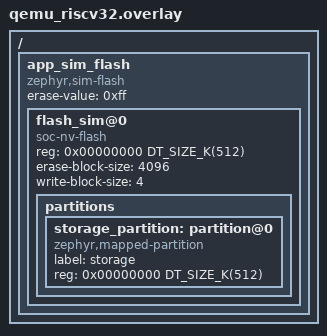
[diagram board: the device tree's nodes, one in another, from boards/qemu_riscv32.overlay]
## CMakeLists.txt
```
# SPDX-License-Identifier: Apache-2.0

cmake_minimum_required(VERSION 3.20.0)
find_package(Zephyr REQUIRED HINTS $ENV{ZEPHYR_BASE})
project(app_fs_sandbox)

zephyr_syscall_header(${CMAKE_CURRENT_SOURCE_DIR}/src/fs_svc.h)

target_sources(app PRIVATE
  src/main.c
  src/fs_broker.c
  src/fs_svc.c
)
```

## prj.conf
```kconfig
CONFIG_USERSPACE=y
CONFIG_APPLICATION_DEFINED_SYSCALL=y

CONFIG_FLASH=y
CONFIG_FLASH_MAP=y
CONFIG_FILE_SYSTEM=y
CONFIG_FILE_SYSTEM_LITTLEFS=y

CONFIG_LOG=y
CONFIG_LOG_MODE_MINIMAL=y
CONFIG_THREAD_NAME=y

CONFIG_MAIN_STACK_SIZE=4096
CONFIG_HEAP_MEM_POOL_SIZE=16384
CONFIG_PRIVILEGED_STACK_SIZE=3072
```

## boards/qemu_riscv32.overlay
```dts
/*
 * Copyright (c) 2026 Espressif Systems (Shanghai) Co., Ltd.
 *
 * SPDX-License-Identifier: Apache-2.0
 */

#include <mem.h>

/* QEMU has no flash for the application store: back the storage partition
 * with the flash simulator.
 */
/ {
	app_sim_flash: app_sim_flash {
		compatible = "zephyr,sim-flash";
		#address-cells = <1>;
		#size-cells = <1>;
		erase-value = <0xff>;

		flash_sim@0 {
			compatible = "soc-nv-flash";
			reg = <0x00000000 DT_SIZE_K(512)>;
			erase-block-size = <4096>;
			write-block-size = <4>;

			partitions {
				ranges;
				#address-cells = <1>;
				#size-cells = <1>;

				storage_partition: partition@0 {
					compatible = "zephyr,mapped-partition";
					label = "storage";
					reg = <0x00000000 DT_SIZE_K(512)>;
				};
			};
		};
	};
};
```

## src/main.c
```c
/*
 * Copyright (c) 2026 Espressif Systems (Shanghai) Co., Ltd.
 *
 * SPDX-License-Identifier: Apache-2.0
 */

/*
 * Per-app sandboxed filesystem. The app reads and writes files in its own
 * private namespace as if it had a whole filesystem, but it is confined to that
 * subtree: a path that tries to escape (absolute, or containing "..") is denied
 * by the broker before any real filesystem access. This is the namespaced
 * storage capability - one shared filesystem, private per-app views.
 */

#include "fs_svc.h"
#include "fs_broker.h"

#include <zephyr/kernel.h>
#include <zephyr/sys/printk.h>
#include <string.h>

#define STACK_SIZE 2048
#define APP_PRIO   5

K_THREAD_STACK_DEFINE(app_stack, STACK_SIZE);
static struct k_thread app_thread;

static void app_entry(void *p1, void *p2, void *p3)
{
	ARG_UNUSED(p1); ARG_UNUSED(p2); ARG_UNUSED(p3);

	printk("\n=== app uses its own private storage ===\n");

	/* Write a file in the app's own namespace. */
	int h = app_file_open("config.txt", 1);

	if (h >= 0) {
		const char *data = "brightness=80\n";

		app_file_write(h, data, strlen(data));
		app_file_close(h);
		printk("  [app] wrote config.txt\n");
	}

	/* Read it back. */
	h = app_file_open("config.txt", 0);
	if (h >= 0) {
		char buf[32] = {0};
		int n = app_file_read(h, buf, sizeof(buf) - 1);

		app_file_close(h);
		printk("  [app] read config.txt (%d bytes): %s", n, buf);
	}

	/* Now try to ESCAPE the sandbox - these must all be denied. */
	printk("\n=== app tries to escape its sandbox (must be denied) ===\n");

	printk("  [app] try '../1/secret.txt' (another app's dir)...\n");
	int rc = app_file_open("../1/secret.txt", 0);

	printk("  [app] -> rc=%d (%s)\n", rc, rc < 0 ? "DENIED" : "LEAKED!");

	printk("  [app] try '/lfs/system/keys' (absolute, system path)...\n");
	rc = app_file_open("/lfs/system/keys", 0);
	printk("  [app] -> rc=%d (%s)\n", rc, rc < 0 ? "DENIED" : "LEAKED!");

	printk("  [app] try 'a/../../etc' (sneaky traversal)...\n");
	rc = app_file_open("a/../../etc", 0);
	printk("  [app] -> rc=%d (%s)\n", rc, rc < 0 ? "DENIED" : "LEAKED!");
}

int main(void)
{
	printk("\n*** per-app sandboxed filesystem (C6) ***\n");

	if (fs_broker_init() != 0) {
		printk("fs_broker_init failed\n");
		return 0;
	}

	k_tid_t t = k_thread_create(&app_thread, app_stack, STACK_SIZE, app_entry,
				    NULL, NULL, NULL, APP_PRIO, K_USER, K_FOREVER);

	/* This app gets namespace 0: /lfs/apps/0/. */
	fs_broker_register(t);

	k_thread_start(t);
	k_thread_join(t, K_FOREVER);

	printk("\n*** done: app used its private storage; all escapes denied ***\n");
	return 0;
}
```

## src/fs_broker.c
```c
/*
 * Copyright (c) 2026 Espressif Systems (Shanghai) Co., Ltd.
 *
 * SPDX-License-Identifier: Apache-2.0
 */

#include "fs_broker.h"

#include <zephyr/kernel.h>
#include <zephyr/sys/printk.h>
#include <zephyr/fs/fs.h>
#include <zephyr/fs/littlefs.h>
#include <zephyr/storage/flash_map.h>
#include <string.h>
#include <errno.h>

#define MOUNT_POINT "/lfs"

FS_LITTLEFS_DECLARE_DEFAULT_CONFIG(lfs_cfg);
static struct fs_mount_t mnt = {
	.type = FS_LITTLEFS,
	.fs_data = &lfs_cfg,
	.storage_dev = (void *)PARTITION_ID(storage_partition),
	.mnt_point = MOUNT_POINT,
};

/* Per-app namespace registry. */
static k_tid_t app_tids[FS_MAX_APPS];
static int app_n;

/* Open-file table (handles are indices). */
static struct fs_file_t files[FS_OPEN_FILES];
static bool file_used[FS_OPEN_FILES];

static int app_id_of_current(void)
{
	k_tid_t cur = k_current_get();

	for (int i = 0; i < FS_MAX_APPS; i++) {
		if (app_tids[i] == cur) {
			return i;
		}
	}
	return -1;
}

/*
 * The security-critical function: build the absolute path for the calling app
 * inside its own namespace, rejecting any attempt to escape it. A safe relative
 * path maps to "/lfs/apps/<id>/<rel>". An absolute path, or one containing a
 * ".." component, is denied.
 */
static int confine_path(int app_id, const char *rel, char *out, size_t out_sz)
{
	if (rel == NULL || rel[0] == '\0') {
		return -EINVAL;
	}
	if (rel[0] == '/') {
		printk("    [fs-broker] DENIED absolute path '%s' (escape)\n", rel);
		return -EACCES;
	}

	/* Reject any ".." path component. */
	for (const char *p = rel; *p != '\0'; p++) {
		if (p[0] == '.' && p[1] == '.' &&
		    (p[2] == '/' || p[2] == '\0') &&
		    (p == rel || p[-1] == '/')) {
			printk("    [fs-broker] DENIED path traversal '%s' (escape)\n",
			       rel);
			return -EACCES;
		}
	}

	int n = snprintk(out, out_sz, MOUNT_POINT "/apps/%d/%s", app_id, rel);

	if (n < 0 || (size_t)n >= out_sz) {
		return -ENAMETOOLONG;
	}
	return 0;
}

static int ensure_app_dir(int app_id)
{
	char dir[FS_PATH_MAX];

	(void)snprintk(dir, sizeof(dir), MOUNT_POINT "/apps");
	(void)fs_mkdir(dir);
	(void)snprintk(dir, sizeof(dir), MOUNT_POINT "/apps/%d", app_id);
	int rc = fs_mkdir(dir);

	return (rc == 0 || rc == -EEXIST) ? 0 : rc;
}

int fs_broker_init(void)
{
	int rc = fs_mount(&mnt);

	if (rc != 0 && rc != -EBUSY) {
		printk("fs-broker: mount failed: %d\n", rc);
		return rc;
	}
	(void)fs_mkdir(MOUNT_POINT "/apps");
	printk("fs-broker: filesystem mounted at %s\n", MOUNT_POINT);
	return 0;
}

int fs_broker_register(k_tid_t tid)
{
	if (app_n >= FS_MAX_APPS) {
		return -ENOSPC;
	}
	int id = app_n++;

	app_tids[id] = tid;
	ensure_app_dir(id);
	return id;
}

int fs_broker_open(const char *rel_path, bool create)
{
	int app_id = app_id_of_current();

	if (app_id < 0) {
		return -EPERM;
	}

	char path[FS_PATH_MAX];
	int rc = confine_path(app_id, rel_path, path, sizeof(path));

	if (rc != 0) {
		return rc;   /* escape denied here */
	}

	int h = -1;

	for (int i = 0; i < FS_OPEN_FILES; i++) {
		if (!file_used[i]) {
			h = i;
			break;
		}
	}
	if (h < 0) {
		return -EMFILE;
	}

	fs_file_t_init(&files[h]);
	fs_mode_t flags = FS_O_RDWR | (create ? FS_O_CREATE : 0);

	rc = fs_open(&files[h], path, flags);
	if (rc != 0) {
		return rc;
	}
	file_used[h] = true;
	printk("    [fs-broker] app %d opened '%s' -> %s (handle %d)\n",
	       app_id, rel_path, path, h);
	return h;
}

int fs_broker_write(int handle, const char *data, size_t len)
{
	if (handle < 0 || handle >= FS_OPEN_FILES || !file_used[handle]) {
		return -EBADF;
	}
	return (int)fs_write(&files[handle], data, len);
}

int fs_broker_read(int handle, char *buf, size_t len)
{
	if (handle < 0 || handle >= FS_OPEN_FILES || !file_used[handle]) {
		return -EBADF;
	}
	(void)fs_seek(&files[handle], 0, FS_SEEK_SET);
	return (int)fs_read(&files[handle], buf, len);
}

int fs_broker_close(int handle)
{
	if (handle < 0 || handle >= FS_OPEN_FILES || !file_used[handle]) {
		return -EBADF;
	}
	fs_close(&files[handle]);
	file_used[handle] = false;
	return 0;
}
```

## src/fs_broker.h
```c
/*
 * Copyright (c) 2026 Espressif Systems (Shanghai) Co., Ltd.
 *
 * SPDX-License-Identifier: Apache-2.0
 */

#ifndef APP_FS_SANDBOX_FS_BROKER_H_
#define APP_FS_SANDBOX_FS_BROKER_H_

#include <zephyr/kernel.h>

/*
 * Per-app sandboxed filesystem - the namespaced-scoped capability. The platform
 * owns one filesystem mount; each app is confined to its own subtree
 * "/lfs/apps/<id>/". An app names files relative to that root and cannot escape
 * it: any path that is absolute or contains a ".." component is rejected before
 * the real filesystem is touched. This is how a phone gives each app its own
 * private storage on one shared filesystem.
 *
 * Files are brokered (open/read/write/close run in supervisor mode) so the
 * confinement is enforced where the app cannot bypass it.
 */

#define FS_MAX_APPS   4
#define FS_PATH_MAX   64
#define FS_OPEN_FILES 4

/* Initialize: mount the filesystem and prepare per-app namespaces. */
int fs_broker_init(void);

/* Register an app thread and give it a numbered namespace. */
int fs_broker_register(k_tid_t tid);

/* Brokered file ops, confined to the caller's namespace. Return a small handle
 * (>=0) from open; negative errno on error (incl. -EACCES for an escape).
 */
int fs_broker_open(const char *rel_path, bool create);
int fs_broker_write(int handle, const char *data, size_t len);
int fs_broker_read(int handle, char *buf, size_t len);
int fs_broker_close(int handle);

#endif /* APP_FS_SANDBOX_FS_BROKER_H_ */
```

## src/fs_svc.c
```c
/*
 * Copyright (c) 2026 Espressif Systems (Shanghai) Co., Ltd.
 *
 * SPDX-License-Identifier: Apache-2.0
 */

#include "fs_svc.h"
#include "fs_broker.h"

#include <zephyr/kernel.h>
#include <zephyr/internal/syscall_handler.h>

#define NAME_MAX 48

int z_impl_app_file_open(const char *path, int create)
{
	return fs_broker_open(path, create != 0);
}

int z_impl_app_file_write(int handle, const char *data, size_t len)
{
	return fs_broker_write(handle, data, len);
}

int z_impl_app_file_read(int handle, char *buf, size_t len)
{
	return fs_broker_read(handle, buf, len);
}

int z_impl_app_file_close(int handle)
{
	return fs_broker_close(handle);
}

#ifdef CONFIG_USERSPACE

static inline int z_vrfy_app_file_open(const char *path, int create)
{
	char copy[NAME_MAX];

	if (k_usermode_string_copy(copy, (char *)path, sizeof(copy)) != 0) {
		return -EFAULT;
	}
	return z_impl_app_file_open(copy, create);
}
#include <zephyr/syscalls/app_file_open_mrsh.c>

static inline int z_vrfy_app_file_write(int handle, const char *data, size_t len)
{
	K_OOPS(K_SYSCALL_MEMORY_READ(data, len));
	return z_impl_app_file_write(handle, data, len);
}
#include <zephyr/syscalls/app_file_write_mrsh.c>

static inline int z_vrfy_app_file_read(int handle, char *buf, size_t len)
{
	K_OOPS(K_SYSCALL_MEMORY_WRITE(buf, len));
	return z_impl_app_file_read(handle, buf, len);
}
#include <zephyr/syscalls/app_file_read_mrsh.c>

static inline int z_vrfy_app_file_close(int handle)
{
	return z_impl_app_file_close(handle);
}
#include <zephyr/syscalls/app_file_close_mrsh.c>

#endif /* CONFIG_USERSPACE */
```

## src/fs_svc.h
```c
/*
 * Copyright (c) 2026 Espressif Systems (Shanghai) Co., Ltd.
 *
 * SPDX-License-Identifier: Apache-2.0
 */

#ifndef APP_FS_SANDBOX_FS_SVC_H_
#define APP_FS_SANDBOX_FS_SVC_H_

#include <zephyr/kernel.h>

/*
 * SDK file API. An app names files relative to its own private root and gets a
 * filesystem view confined to that subtree. Escapes are denied by the broker.
 */

__syscall int app_file_open(const char *path, int create);
__syscall int app_file_write(int handle, const char *data, size_t len);
__syscall int app_file_read(int handle, char *buf, size_t len);
__syscall int app_file_close(int handle);

#include <zephyr/syscalls/fs_svc.h>

#endif /* APP_FS_SANDBOX_FS_SVC_H_ */
```
